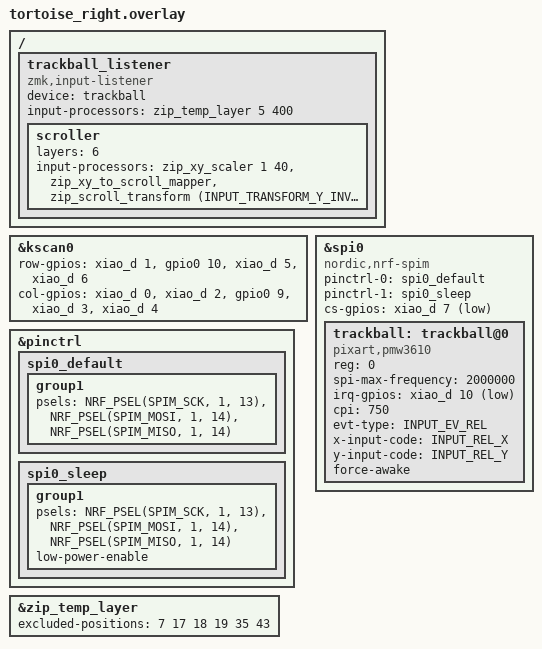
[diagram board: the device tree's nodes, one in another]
#include "tortoise.dtsi"
#include <input/processors.dtsi>

&kscan0 {
    row-gpios
        = <&xiao_d 1 (GPIO_ACTIVE_HIGH | GPIO_PULL_DOWN)> 
        , <&gpio0 10 (GPIO_ACTIVE_HIGH | GPIO_PULL_DOWN)>
        , <&xiao_d 5 (GPIO_ACTIVE_HIGH | GPIO_PULL_DOWN)>
        , <&xiao_d 6 (GPIO_ACTIVE_HIGH | GPIO_PULL_DOWN)> 
        ;
    col-gpios
        = <&xiao_d 0 GPIO_ACTIVE_HIGH>	
        , <&xiao_d 2 GPIO_ACTIVE_HIGH> 
        , <&gpio0 9 GPIO_ACTIVE_HIGH> 
        , <&xiao_d 3 GPIO_ACTIVE_HIGH> 
        , <&xiao_d 4 GPIO_ACTIVE_HIGH> 
        ;
};

&pinctrl {
    spi0_default: spi0_default {    //通常時(SPI通信中)のピン構成
        group1 {
            psels = <NRF_PSEL(SPIM_SCK, 1, 13)>,    //(SCLK)
                    <NRF_PSEL(SPIM_MOSI, 1, 14)>,   //(SDIOだからMOSI,MISO両方の役割を担う)
                    <NRF_PSEL(SPIM_MISO, 1, 14)>;
        };
    };

    spi0_sleep: spi0_sleep {    //スリープ時のピン構成(省電力)
        group1 {
            psels = <NRF_PSEL(SPIM_SCK, 1, 13)>,
                    <NRF_PSEL(SPIM_MOSI, 1, 14)>,
                    <NRF_PSEL(SPIM_MISO, 1, 14)>;
            low-power-enable;
        };
    };
};

#include <zephyr/dt-bindings/input/input-event-codes.h>

&spi0 {
    status = "okay";
    compatible = "nordic,nrf-spim"; //マイコンがnRFシリーズ
    pinctrl-0 = <&spi0_default>;
    pinctrl-1 = <&spi0_sleep>;
    pinctrl-names = "default", "sleep";
    cs-gpios = <&xiao_d 7 GPIO_ACTIVE_LOW>;  //(CS)

    trackball: trackball@0 {
        status = "okay";
        compatible = "pixart,pmw3610";  //トラボセンサ用のドライバとバインド
        reg = <0>;
        spi-max-frequency = <2000000>;
        irq-gpios = <&xiao_d 10 (GPIO_ACTIVE_LOW | GPIO_PULL_UP)>; //(MOTION)
        cpi = <750>;
        evt-type = <INPUT_EV_REL>;
        x-input-code = <INPUT_REL_X>;
        y-input-code = <INPUT_REL_Y>;

        force-awake;
    };
};

&zip_temp_layer {
    excluded-positions = <
        7
        17 
        18
        19 
        35
        43
    >;
};

/ {
    trackball_listener {
        compatible = "zmk,input-listener";
        device = <&trackball>;
        input-processors = <&zip_temp_layer 5 400>;
        
        scroller {
            layers = <6>;
            input-processors = <&zip_xy_scaler 1 40 &zip_xy_to_scroll_mapper>, <&zip_scroll_transform (INPUT_TRANSFORM_Y_INVERT)>;
        };
    };
};
